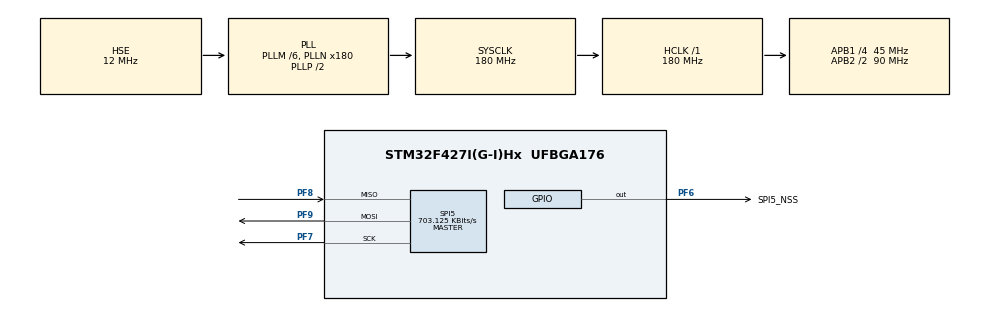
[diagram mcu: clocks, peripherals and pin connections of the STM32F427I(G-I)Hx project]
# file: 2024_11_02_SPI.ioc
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Mcu.Family=STM32F4
Mcu.Name=STM32F427I(G-I)Hx
Mcu.Package=UFBGA176
NVIC.PriorityGroup=NVIC_PRIORITYGROUP_4
NVIC.TIM1_BRK_TIM9_IRQn=true\:0\:0\:false\:false\:true\:true\:true\:true
NVIC.TIM1_CC_IRQn=true\:0\:0\:false\:false\:true\:true\:true\:true
NVIC.TIM1_TRG_COM_TIM11_IRQn=true\:0\:0\:false\:false\:true\:true\:true\:true
NVIC.TIM1_UP_TIM10_IRQn=true\:0\:0\:false\:false\:true\:true\:true\:true
PA13.Mode=Serial_Wire
PA13.Signal=SYS_JTMS-SWDIO
PA14.Mode=Serial_Wire
PA14.Signal=SYS_JTCK-SWCLK
PF6.GPIO_Label=SPI5_NSS
PF6.Signal=GPIO_Output
PF7.GPIO_Mode=GPIO_MODE_AF_PP
PF7.GPIO_PuPd=GPIO_NOPULL
PF7.GPIO_Speed=GPIO_SPEED_FREQ_VERY_HIGH
PF7.Mode=Full_Duplex_Master
PF7.Signal=SPI5_SCK
PF8.GPIO_Mode=GPIO_MODE_AF_PP
PF8.GPIO_PuPd=GPIO_NOPULL
PF8.GPIO_Speed=GPIO_SPEED_FREQ_VERY_HIGH
PF8.Mode=Full_Duplex_Master
PF8.Signal=SPI5_MISO
PF9.GPIO_Mode=GPIO_MODE_AF_PP
PF9.GPIO_PuPd=GPIO_NOPULL
PF9.GPIO_Speed=GPIO_SPEED_FREQ_VERY_HIGH
PF9.Mode=Full_Duplex_Master
PF9.Signal=SPI5_MOSI
PH0/OSC_IN.Mode=HSE-External-Oscillator
PH0/OSC_IN.Signal=RCC_OSC_IN
PH1/OSC_OUT.Mode=HSE-External-Oscillator
PH1/OSC_OUT.Signal=RCC_OSC_OUT
ProjectManager.HeapSize=0x200
ProjectManager.StackSize=0x400
ProjectManager.TargetToolchain=STM32CubeIDE
RCC.48MHZClocksFreq_Value=90000000
RCC.AHBFreq_Value=180000000
RCC.APB1CLKDivider=RCC_HCLK_DIV4
RCC.APB1Freq_Value=45000000
RCC.APB1TimFreq_Value=90000000
RCC.APB2CLKDivider=RCC_HCLK_DIV2
RCC.APB2Freq_Value=90000000
RCC.APB2TimFreq_Value=180000000
RCC.CortexFreq_Value=180000000
RCC.HCLKFreq_Value=180000000
RCC.HSE_VALUE=12000000
RCC.HSI_VALUE=16000000
RCC.LSE_VALUE=32768
RCC.PLLM=6
RCC.PLLN=180
RCC.PLLSourceVirtual=RCC_PLLSOURCE_HSE
RCC.SYSCLKFreq_VALUE=180000000
RCC.SYSCLKSource=RCC_SYSCLKSOURCE_PLLCLK
RCC.VCOOutputFreq_Value=360000000
SPI5.BaudRatePrescaler=SPI_BAUDRATEPRESCALER_128
SPI5.CalculateBaudRate=703.125 KBits/s
SPI5.Direction=SPI_DIRECTION_2LINES
SPI5.Mode=SPI_MODE_MASTER
SPI5.VirtualType=VM_MASTER
TIM1.Period=4999
TIM1.Prescaler=179
VP_TIM1_VS_ClockSourceINT.Mode=Internal
board=custom

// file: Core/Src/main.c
/* USER CODE BEGIN Header */
/**
  ******************************************************************************
  * @file           : main.c
  * @brief          : Main program body
  ******************************************************************************
  * @attention
  *
  * Copyright (c) 2024 STMicroelectronics.
  * All rights reserved.
  *
  * This software is licensed under terms that can be found in the LICENSE file
  * in the root directory of this software component.
  * If no LICENSE file comes with this software, it is provided AS-IS.
  *
  ******************************************************************************
  */
/* USER CODE END Header */
#include "tim.h"
#include "gpio.h"
#include "main.h"
#include "spi.h"
#include "mpu.h"

/* USER CODE BEGIN PV */
float x_accel,y_accel,z_accel;
float x_gyro,y_gyro,z_gyro;
/* USER CODE END PV */

void SystemClock_Config(void);

int main(void)
{

  /* MCU Configuration--------------------------------------------------------*/

  /* Reset of all peripherals, Initializes the Flash interface and the Systick. */
  HAL_Init();

  /* Configure the system clock */
  SystemClock_Config();

  /* Initialize all configured peripherals */
  MX_GPIO_Init();
  MX_SPI5_Init();
  MX_TIM1_Init();
  /* USER CODE BEGIN 2 */
  HAL_TIM_Base_Start_IT(&htim1);
  MPU6500_Init();
  /* USER CODE END 2 */

  /* Infinite loop */
  while (1)
  {

  }
}

void SystemClock_Config(void)
{
  RCC_OscInitTypeDef RCC_OscInitStruct = {0};
  RCC_ClkInitTypeDef RCC_ClkInitStruct = {0};

  /** Configure the main internal regulator output voltage
  */
  __HAL_RCC_PWR_CLK_ENABLE();
  __HAL_PWR_VOLTAGESCALING_CONFIG(PWR_REGULATOR_VOLTAGE_SCALE1);

  /** Initializes the RCC Oscillators according to the specified parameters
  * in the RCC_OscInitTypeDef structure.
  */
  RCC_OscInitStruct.OscillatorType = RCC_OSCILLATORTYPE_HSE;
  RCC_OscInitStruct.HSEState = RCC_HSE_ON;
  RCC_OscInitStruct.PLL.PLLState = RCC_PLL_ON;
  RCC_OscInitStruct.PLL.PLLSource = RCC_PLLSOURCE_HSE;
  RCC_OscInitStruct.PLL.PLLM = 6;
  RCC_OscInitStruct.PLL.PLLN = 180;
  RCC_OscInitStruct.PLL.PLLP = RCC_PLLP_DIV2;
  RCC_OscInitStruct.PLL.PLLQ = 4;
  if (HAL_RCC_OscConfig(&RCC_OscInitStruct) != HAL_OK)
  {
    Error_Handler();
  }

  /** Activate the Over-Drive mode
  */
  if (HAL_PWREx_EnableOverDrive() != HAL_OK)
  {
    Error_Handler();
  }

  /** Initializes the CPU, AHB and APB buses clocks
  */
  RCC_ClkInitStruct.ClockType = RCC_CLOCKTYPE_HCLK|RCC_CLOCKTYPE_SYSCLK
                              |RCC_CLOCKTYPE_PCLK1|RCC_CLOCKTYPE_PCLK2;
  RCC_ClkInitStruct.SYSCLKSource = RCC_SYSCLKSOURCE_PLLCLK;
  RCC_ClkInitStruct.AHBCLKDivider = RCC_SYSCLK_DIV1;
  RCC_ClkInitStruct.APB1CLKDivider = RCC_HCLK_DIV4;
  RCC_ClkInitStruct.APB2CLKDivider = RCC_HCLK_DIV2;

  if (HAL_RCC_ClockConfig(&RCC_ClkInitStruct, FLASH_LATENCY_5) != HAL_OK)
  {
    Error_Handler();
  }
}

void Error_Handler(void)
{
  __disable_irq();
  while (1)
  {
  }
}
